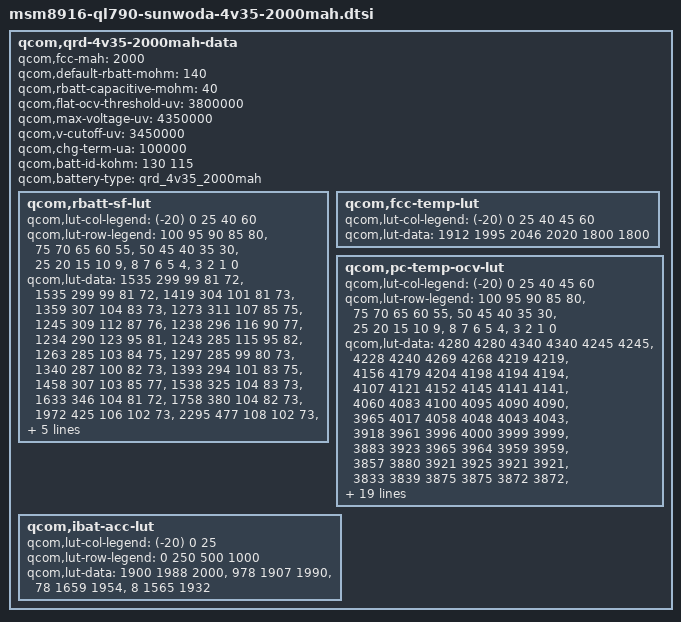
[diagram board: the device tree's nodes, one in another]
/* Copyright (c) 2013, The Linux Foundation. All rights reserved.
 *
 * This program is free software; you can redistribute it and/or modify
 * it under the terms of the GNU General Public License version 2 and
 * only version 2 as published by the Free Software Foundation.
 *
 * This program is distributed in the hope that it will be useful,
 * but WITHOUT ANY WARRANTY; without even the implied warranty of
 * MERCHANTABILITY or FITNESS FOR A PARTICULAR PURPOSE.  See the
 * GNU General Public License for more details.
 */
qcom,qrd-4v35-2000mah-data {
	qcom,fcc-mah = <2000>;
	qcom,default-rbatt-mohm = <140>;
	qcom,rbatt-capacitive-mohm = <40>;
	qcom,flat-ocv-threshold-uv = <3800000>;
	qcom,max-voltage-uv = <4350000>;
	qcom,v-cutoff-uv = <3450000>;
	qcom,chg-term-ua = <100000>;
	qcom,batt-id-kohm = <130 115>;
	qcom,battery-type = "qrd_4v35_2000mah";

	qcom,rbatt-sf-lut {
		qcom,lut-col-legend = <(-20) 0 25 40 60>;
		qcom,lut-row-legend = <100 95 90 85 80>,
				<75 70 65 60 55>,
				<50 45 40 35 30>,
				<25 20 15 10 9>,
				< 8 7 6 5 4>,
				< 3 2 1 0>;
		qcom,lut-data =
			<1535  299  99  81  72>,
			<1535  299  99  81  72>,
			<1419  304  101  81  73>,
			<1359  307  104  83  73>,
			<1273  311  107  85  75>,
			<1245  309  112  87  76>,
			<1238  296  116  90  77>,
			<1234  290  123  95  81>,
			<1243  285  115  95  82>,
			<1263  285  103  84  75>,
			<1297  285  99  80  73>,
			<1340  287  100  82  73>,
			<1393  294  101  83  75>,
			<1458  307  103  85  77>,
			<1538  325  104  83  73>,
			<1633  346  104  81  72>,
			<1758  380  104  82  73>,//20
			<1972  425  106  102  73>,
			<2295  477  108  102  73>,//10
			<2642  427  100  103  74>,
			<2849  458  101  105  75>,
			<3094  487  105  97  76>,
			<3272  503  98  99  77>,
			<4839  542  98  99  76>,
			<6001  522  98  99  75>,
			<7870  533  107  102  78>,
			<7245  504  102  107  83>,
			<7465  576  108  105  101>,
			<7930  652  246  231  143>;
	};

	qcom,fcc-temp-lut {
		qcom,lut-col-legend = <(-20) 0 25 40 45 60>;
		qcom,lut-data = <1912 1995 2046 2020 1800 1800>;
	};

	qcom,pc-temp-ocv-lut {
		qcom,lut-col-legend = <(-20) 0 25 40 45 60>;
		qcom,lut-row-legend = <100 95 90 85 80>,
				<75 70 65 60 55>,
				<50 45 40 35 30>,
				<25 20 15 10 9>,
				< 8 7 6 5 4>,
				< 3 2 1 0>;
		qcom,lut-data =
			<4280 4280 4340 4340 4245 4245>,
			<4228 4240 4269 4268 4219 4219>,
			<4156 4179 4204 4198 4194 4194>, //90
			<4107 4121 4152 4145 4141 4141>,
			<4060 4083 4100 4095 4090 4090>, //80
			<3965 4017 4058 4048 4043 4043>,
			<3918 3961 3996 4000 3999 3999>, //70
			<3883 3923 3965 3964 3959 3959>,
			<3857 3880 3921 3925 3921 3921>, //60
			<3833 3839 3875 3875 3872 3872>,
			<3815 3815 3833 3832 3835 3835>, //50
			<3796 3803 3810 3812 3817 3817>,
			<3777 3786 3791 3790 3794 3794>, //40
			<3759 3772 3770 3771 3773 3773>,
			<3743 3756 3755 3756 3758 3758>, //30
			<3727 3741 3739 3740 3739 3739>,
			<3714 3728 3723 3723 3718 3718>, //20
			<3693 3708 3703 3704 3688 3688>,
			<3681 3691 3691 3691 3681 3681>, //10
			<3670 3680 3680 3680 3670 3670>,
			<3659 3659 3659 3659 3659 3659>,
			<3637 3637 3637 3637 3637 3637>,
			<3615 3615 3615 3615 3615 3615>,
			<3580 3580 3580 3580 3580 3580>, //5
			<3545 3545 3545 3545 3545 3545>,
			<3510 3510 3510 3510 3510 3510>,
			<3480 3480 3480 3480 3480 3480>,
			<3400 3400 3400 3400 3400 3400>,
			<3300 3300 3300 3300 3300 3300>; //0
	};
	qcom,ibat-acc-lut {
		qcom,lut-col-legend = <(-20) 0 25>;
		qcom,lut-row-legend = <0 250 500 1000>;
		qcom,lut-data =
			<1900 1988 2000>,
			<978 1907 1990>,
			<78 1659 1954>,
			<8 1565 1932>;
	};
};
